VERSION ""

NS_ :

BS_:

BU_: XXX

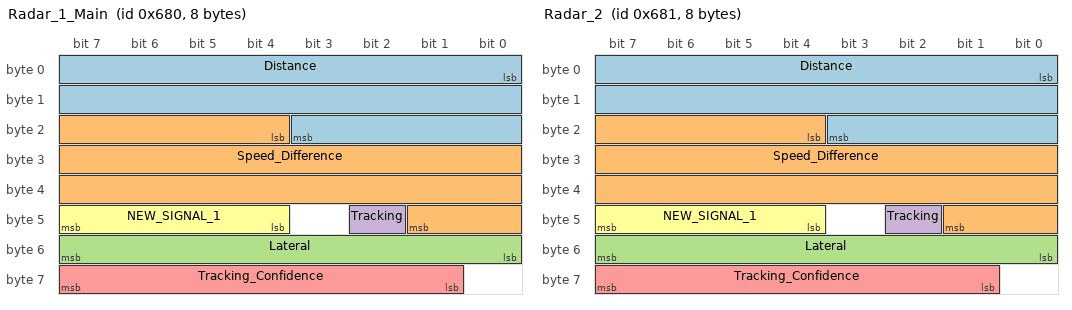
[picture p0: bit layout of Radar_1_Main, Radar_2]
BO_ 1664 Radar_1_Main: 8 XXX
 SG_ Distance : 0|20@1+ (1,0) [0|127] "" XXX
 SG_ Speed_Difference : 20|22@1+ (1,0) [0|65535] "" XXX
 SG_ Lateral : 48|8@1+ (1,-128) [0|3] "" XXX
 SG_ Tracking : 42|1@1+ (1,0) [0|3] "" XXX
 SG_ Tracking_Confidence : 57|7@1+ (1,0) [0|3] "" XXX
 SG_ NEW_SIGNAL_1 : 47|4@0+ (1,0) [0|63] "" XXX

BO_ 1665 Radar_2: 8 XXX
 SG_ Distance : 0|20@1+ (1,0) [0|127] "" XXX
 SG_ Speed_Difference : 20|22@1+ (1,0) [0|65535] "" XXX
 SG_ Lateral : 48|8@1+ (1,-128) [0|3] "" XXX
 SG_ Tracking : 42|1@1+ (1,0) [0|3] "" XXX
 SG_ Tracking_Confidence : 57|7@1+ (1,0) [0|3] "" XXX
 SG_ NEW_SIGNAL_1 : 47|4@0+ (1,0) [0|63] "" XXX

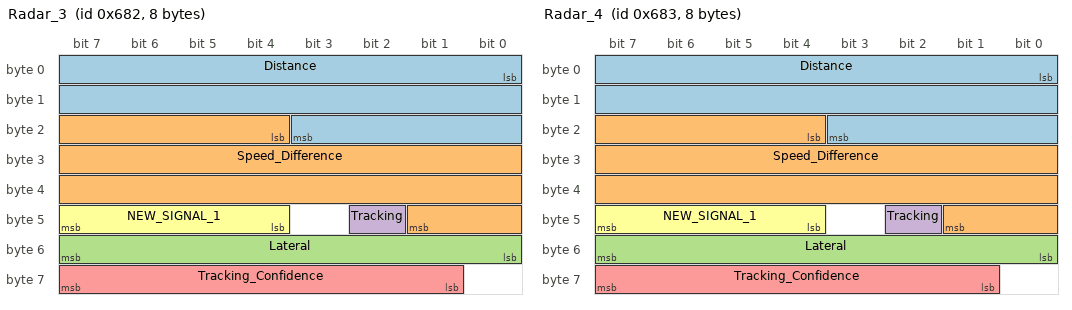
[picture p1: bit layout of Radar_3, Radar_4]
BO_ 1666 Radar_3: 8 XXX
 SG_ Distance : 0|20@1+ (1,0) [0|127] "" XXX
 SG_ Speed_Difference : 20|22@1+ (1,0) [0|65535] "" XXX
 SG_ Lateral : 48|8@1+ (1,-128) [0|3] "" XXX
 SG_ Tracking : 42|1@1+ (1,0) [0|3] "" XXX
 SG_ Tracking_Confidence : 57|7@1+ (1,0) [0|3] "" XXX
 SG_ NEW_SIGNAL_1 : 47|4@0+ (1,0) [0|63] "" XXX

BO_ 1667 Radar_4: 8 XXX
 SG_ Distance : 0|20@1+ (1,0) [0|127] "" XXX
 SG_ Speed_Difference : 20|22@1+ (1,0) [0|65535] "" XXX
 SG_ Lateral : 48|8@1+ (1,-128) [0|3] "" XXX
 SG_ Tracking : 42|1@1+ (1,0) [0|3] "" XXX
 SG_ Tracking_Confidence : 57|7@1+ (1,0) [0|3] "" XXX
 SG_ NEW_SIGNAL_1 : 47|4@0+ (1,0) [0|63] "" XXX

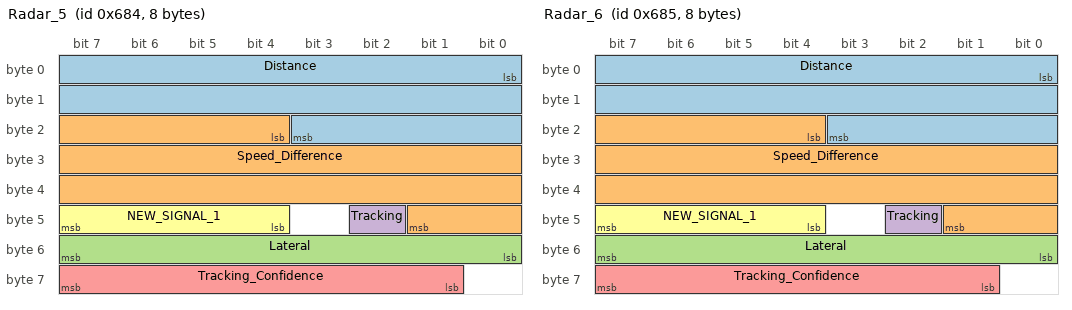
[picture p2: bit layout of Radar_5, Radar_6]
BO_ 1668 Radar_5: 8 XXX
 SG_ Distance : 0|20@1+ (1,0) [0|127] "" XXX
 SG_ Speed_Difference : 20|22@1+ (1,0) [0|65535] "" XXX
 SG_ Lateral : 48|8@1+ (1,-128) [0|3] "" XXX
 SG_ Tracking : 42|1@1+ (1,0) [0|3] "" XXX
 SG_ Tracking_Confidence : 57|7@1+ (1,0) [0|3] "" XXX
 SG_ NEW_SIGNAL_1 : 47|4@0+ (1,0) [0|63] "" XXX

BO_ 1669 Radar_6: 8 XXX
 SG_ Distance : 0|20@1+ (1,0) [0|127] "" XXX
 SG_ Speed_Difference : 20|22@1+ (1,0) [0|65535] "" XXX
 SG_ Lateral : 48|8@1+ (1,-128) [0|3] "" XXX
 SG_ Tracking : 42|1@1+ (1,0) [0|3] "" XXX
 SG_ Tracking_Confidence : 57|7@1+ (1,0) [0|3] "" XXX
 SG_ NEW_SIGNAL_1 : 47|4@0+ (1,0) [0|63] "" XXX

CM_ SG_ 1664 Tracking_Confidence "127 = confident, 87 = kinda confident, 0 = no tracking";
